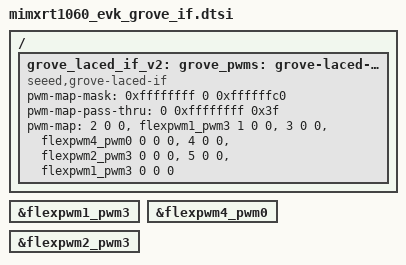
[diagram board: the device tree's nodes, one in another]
/*
 * Copyright (c) 2023 TiaC Systems
 * SPDX-License-Identifier: Apache-2.0
 */

/ {
	grove_laced_if_v2: grove-laced-if-v2 {

		compatible = "seeed,grove-laced-if";

		#pwm-cells = <3>;
		pwm-map-mask = <0xffffffff 0 0xffffffc0>;
		pwm-map-pass-thru = <0 0xffffffff 0x3f>;
		pwm-map =
			/*  0 - D0: not possible */
			/*  1 - D1: not possible */
			<2 0 0 &flexpwm1_pwm3 1 0 0>,	/* D2: PWM1B3 */
			<3 0 0 &flexpwm4_pwm0 0 0 0>,	/* D3: PWM4A0 */
			<4 0 0 &flexpwm2_pwm3 0 0 0>,	/* D4: PWM2A3 */
			<5 0 0 &flexpwm1_pwm3 0 0 0>;	/* D5: PWM1A3 */
			/*  6 - D6: not possible */
			/*  7 - D7: not possible */
			/*  8 - D8: not possible */
			/*  9 - D9: not possible */
			/* 10 - D10: not wired */
			/* 11 - D11: not wired */
			/* 12 - D12: not wired */
			/* 13 - D13: not wired */
			/* 14 - D14: not possible */
			/* 15 - D15: not possible */
			/* 16 - D16: not possible */
			/* 17 - D17: not possible */
			/* 18 - D17: not possible */
			/* 19 - D17: not possible */
	};
};

grove_pwms: &grove_laced_if_v2 {};

grove_pwm_d2: &flexpwm1_pwm3 {};
grove_pwm_d3: &flexpwm4_pwm0 {};
grove_pwm_d4: &flexpwm2_pwm3 {};
grove_pwm_d5: &flexpwm1_pwm3 {};
